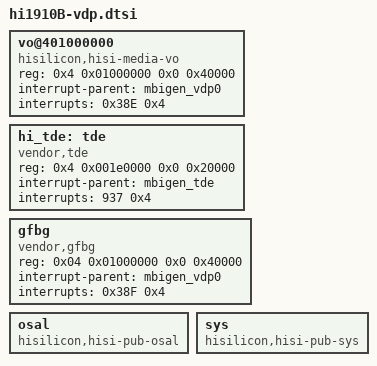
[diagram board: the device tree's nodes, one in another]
    vo@401000000 {
        compatible = "hisilicon,hisi-media-vo";
        reg = <0x4 0x01000000 0x0 0x40000>;
        reg-names = "vo";
        interrupt-parent = <&mbigen_vdp0>;
        interrupts = <0x38E 0x4>;
        interrupt-names = "vdp0";
    };

    hi_tde: tde {
        compatible = "vendor,tde";
        reg = <0x4 0x001e0000 0x0 0x20000>;
        interrupt-parent = <&mbigen_tde>;
        interrupts = <937 0x4>;
        interrupt-names = "tde_osr_isr";
    };

    gfbg {
        compatible = "vendor,gfbg";
        reg = <0x04 0x01000000 0x0 0x40000>;
        interrupt-parent = <&mbigen_vdp0>;
        interrupts = <0x38F 0x4>;
        interrupt-names = "GFBG Int";
    };

    osal {
        compatible = "hisilicon,hisi-pub-osal";
    };

    sys {
        compatible = "hisilicon,hisi-pub-sys";
    };
